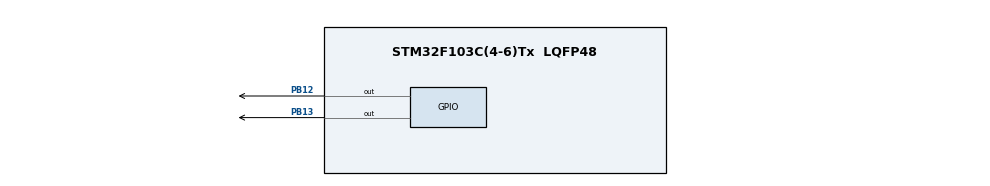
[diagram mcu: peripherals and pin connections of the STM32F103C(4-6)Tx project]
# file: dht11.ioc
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Mcu.Family=STM32F1
Mcu.Name=STM32F103C(4-6)Tx
Mcu.Package=LQFP48
NVIC.PriorityGroup=NVIC_PRIORITYGROUP_4
NVIC.TIM1_BRK_IRQn=true\:0\:0\:false\:false\:true\:true\:true\:true
NVIC.TIM1_CC_IRQn=true\:0\:0\:false\:false\:true\:true\:true\:true
NVIC.TIM1_TRG_COM_IRQn=true\:0\:0\:false\:false\:true\:true\:true\:true
NVIC.TIM1_UP_IRQn=true\:0\:0\:false\:false\:true\:true\:true\:true
PA13.Mode=Serial_Wire
PA13.Signal=SYS_JTMS-SWDIO
PA14.Mode=Serial_Wire
PA14.Signal=SYS_JTCK-SWCLK
PB12.Signal=GPIO_Output
PB13.GPIO_ModeDefaultOutputPP=GPIO_MODE_OUTPUT_OD
PB13.GPIO_PuPd=GPIO_NOPULL
PB13.Signal=GPIO_Output
PD0-OSC_IN.Mode=HSE-External-Oscillator
PD0-OSC_IN.Signal=RCC_OSC_IN
PD1-OSC_OUT.Mode=HSE-External-Oscillator
PD1-OSC_OUT.Signal=RCC_OSC_OUT
ProjectManager.HeapSize=0x200
ProjectManager.StackSize=0x400
ProjectManager.TargetToolchain=STM32CubeIDE
RCC.APB1Freq_Value=8000000
RCC.APB2Freq_Value=8000000
RCC.PLLSourceVirtual=RCC_PLLSOURCE_HSE
RCC.SYSCLKSource=RCC_SYSCLKSOURCE_HSE
RCC.USBFreq_Value=16000000
TIM1.Period=65535-1
TIM1.Prescaler=8-1
VP_TIM1_VS_ClockSourceINT.Mode=Internal
board=custom

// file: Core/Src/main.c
/* USER CODE BEGIN Header */
/**
  ******************************************************************************
  * @file           : main.c
  * @brief          : Main program body
  ******************************************************************************
  * @attention
  *
  * Copyright (c) 2024 STMicroelectronics.
  * All rights reserved.
  *
  * This software is licensed under terms that can be found in the LICENSE file
  * in the root directory of this software component.
  * If no LICENSE file comes with this software, it is provided AS-IS.
  *
  ******************************************************************************
  */
/* USER CODE END Header */
#include "main.h"

/* USER CODE BEGIN Includes */
#include "DHT.h"
/* USER CODE END Includes */

TIM_HandleTypeDef htim1;

void SystemClock_Config(void);
static void MX_GPIO_Init(void);
static void MX_TIM1_Init(void);

/* USER CODE BEGIN 0 */

DHT_DataTypedef DHT11_Data;
float Temperature, Humidity;

/* USER CODE END 0 */

int main(void)
{

  /* MCU Configuration--------------------------------------------------------*/

  /* Reset of all peripherals, Initializes the Flash interface and the Systick. */
  HAL_Init();

  /* Configure the system clock */
  SystemClock_Config();

  /* Initialize all configured peripherals */
  MX_GPIO_Init();
  MX_TIM1_Init();

  /* Infinite loop */
  while (1)
  {

    /* USER CODE BEGIN 3 */
	  HAL_GPIO_WritePin(GPIOB, 12, 1);
	  DHT_GetData(&DHT11_Data);
  	  Temperature = DHT11_Data.Temperature;
	  Humidity = DHT11_Data.Humidity;
	  HAL_Delay(1500);
	  HAL_GPIO_WritePin(GPIOB, 12, 0);
	  HAL_Delay(1500);
  }

  /* USER CODE END 3 */
}

void SystemClock_Config(void)
{
  RCC_OscInitTypeDef RCC_OscInitStruct = {0};
  RCC_ClkInitTypeDef RCC_ClkInitStruct = {0};

  /** Initializes the RCC Oscillators according to the specified parameters
  * in the RCC_OscInitTypeDef structure.
  */
  RCC_OscInitStruct.OscillatorType = RCC_OSCILLATORTYPE_HSE;
  RCC_OscInitStruct.HSEState = RCC_HSE_ON;
  RCC_OscInitStruct.PLL.PLLState = RCC_PLL_NONE;
  if (HAL_RCC_OscConfig(&RCC_OscInitStruct) != HAL_OK)
  {
    Error_Handler();
  }

  /** Initializes the CPU, AHB and APB buses clocks
  */
  RCC_ClkInitStruct.ClockType = RCC_CLOCKTYPE_HCLK|RCC_CLOCKTYPE_SYSCLK
                              |RCC_CLOCKTYPE_PCLK1|RCC_CLOCKTYPE_PCLK2;
  RCC_ClkInitStruct.SYSCLKSource = RCC_SYSCLKSOURCE_HSE;
  RCC_ClkInitStruct.AHBCLKDivider = RCC_SYSCLK_DIV1;
  RCC_ClkInitStruct.APB1CLKDivider = RCC_HCLK_DIV1;
  RCC_ClkInitStruct.APB2CLKDivider = RCC_HCLK_DIV1;

  if (HAL_RCC_ClockConfig(&RCC_ClkInitStruct, FLASH_LATENCY_0) != HAL_OK)
  {
    Error_Handler();
  }
}

static void MX_TIM1_Init(void)
{

  TIM_ClockConfigTypeDef sClockSourceConfig = {0};
  TIM_MasterConfigTypeDef sMasterConfig = {0};

  htim1.Instance = TIM1;
  htim1.Init.Prescaler = 8-1;
  htim1.Init.CounterMode = TIM_COUNTERMODE_UP;
  htim1.Init.Period = 65535-1;
  htim1.Init.ClockDivision = TIM_CLOCKDIVISION_DIV1;
  htim1.Init.RepetitionCounter = 0;
  htim1.Init.AutoReloadPreload = TIM_AUTORELOAD_PRELOAD_DISABLE;
  if (HAL_TIM_Base_Init(&htim1) != HAL_OK)
  {
    Error_Handler();
  }
  sClockSourceConfig.ClockSource = TIM_CLOCKSOURCE_INTERNAL;
  if (HAL_TIM_ConfigClockSource(&htim1, &sClockSourceConfig) != HAL_OK)
  {
    Error_Handler();
  }
  sMasterConfig.MasterOutputTrigger = TIM_TRGO_RESET;
  sMasterConfig.MasterSlaveMode = TIM_MASTERSLAVEMODE_DISABLE;
  if (HAL_TIMEx_MasterConfigSynchronization(&htim1, &sMasterConfig) != HAL_OK)
  {
    Error_Handler();
  }

}

static void MX_GPIO_Init(void)
{
  GPIO_InitTypeDef GPIO_InitStruct = {0};

  /* GPIO Ports Clock Enable */
  __HAL_RCC_GPIOD_CLK_ENABLE();
  __HAL_RCC_GPIOB_CLK_ENABLE();
  __HAL_RCC_GPIOA_CLK_ENABLE();

  /*Configure GPIO pin Output Level */
  HAL_GPIO_WritePin(GPIOB, GPIO_PIN_12|GPIO_PIN_13, GPIO_PIN_RESET);

  /*Configure GPIO pin : PB12 */
  GPIO_InitStruct.Pin = GPIO_PIN_12;
  GPIO_InitStruct.Mode = GPIO_MODE_OUTPUT_PP;
  GPIO_InitStruct.Pull = GPIO_NOPULL;
  GPIO_InitStruct.Speed = GPIO_SPEED_FREQ_LOW;
  HAL_GPIO_Init(GPIOB, &GPIO_InitStruct);

  /*Configure GPIO pin : PB13 */
  GPIO_InitStruct.Pin = GPIO_PIN_13;
  GPIO_InitStruct.Mode = GPIO_MODE_OUTPUT_OD;
  GPIO_InitStruct.Pull = GPIO_NOPULL;
  GPIO_InitStruct.Speed = GPIO_SPEED_FREQ_LOW;
  HAL_GPIO_Init(GPIOB, &GPIO_InitStruct);

}

void Error_Handler(void)
{
  __disable_irq();
  while (1)
  {
  }
}
